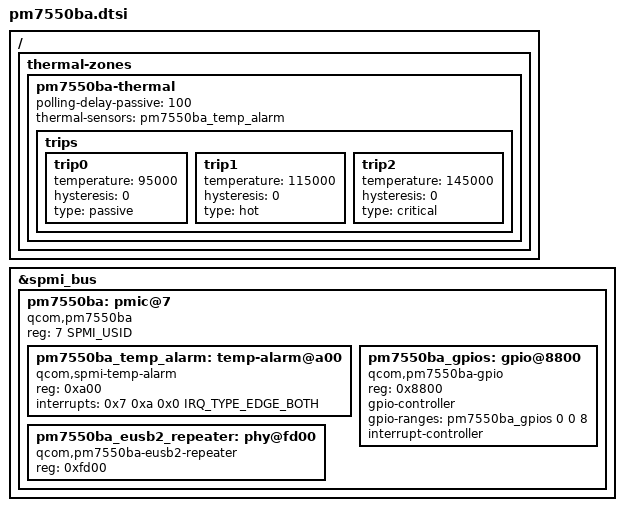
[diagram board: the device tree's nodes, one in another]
// SPDX-License-Identifier: BSD-3-Clause
/*
 * Copyright (c) 2023 Qualcomm Innovation Center, Inc. All rights reserved.
 */

#include <dt-bindings/interrupt-controller/irq.h>
#include <dt-bindings/spmi/spmi.h>

/ {
	thermal-zones {
		pm7550ba-thermal {
			polling-delay-passive = <100>;

			thermal-sensors = <&pm7550ba_temp_alarm>;

			trips {
				trip0 {
					temperature = <95000>;
					hysteresis = <0>;
					type = "passive";
				};

				trip1 {
					temperature = <115000>;
					hysteresis = <0>;
					type = "hot";
				};

				trip2 {
					temperature = <145000>;
					hysteresis = <0>;
					type = "critical";
				};
			};
		};
	};
};

&spmi_bus {
	pm7550ba: pmic@7 {
		compatible = "qcom,pm7550ba", "qcom,spmi-pmic";
		reg = <7 SPMI_USID>;
		#address-cells = <1>;
		#size-cells = <0>;

		pm7550ba_temp_alarm: temp-alarm@a00 {
			compatible = "qcom,spmi-temp-alarm";
			reg = <0xa00>;
			interrupts = <0x7 0xa 0x0 IRQ_TYPE_EDGE_BOTH>;
			#thermal-sensor-cells = <0>;
		};

		pm7550ba_gpios: gpio@8800 {
			compatible = "qcom,pm7550ba-gpio", "qcom,spmi-gpio";
			reg = <0x8800>;
			gpio-controller;
			gpio-ranges = <&pm7550ba_gpios 0 0 8>;
			#gpio-cells = <2>;
			interrupt-controller;
			#interrupt-cells = <2>;
		};

		pm7550ba_eusb2_repeater: phy@fd00 {
			compatible = "qcom,pm7550ba-eusb2-repeater", "qcom,pm8550b-eusb2-repeater";
			reg = <0xfd00>;
			#phy-cells = <0>;
		};
	};
};
